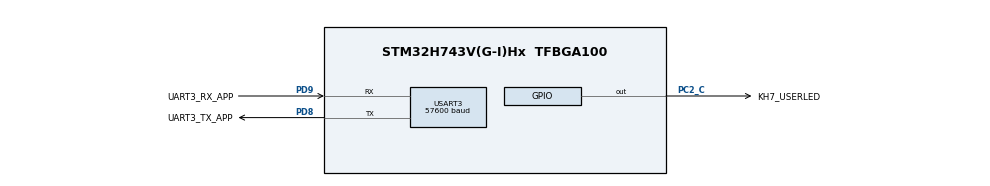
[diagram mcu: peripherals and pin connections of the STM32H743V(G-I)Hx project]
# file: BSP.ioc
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CORTEX_M7.default_mode_Activation=0
Mcu.Family=STM32H7
Mcu.Name=STM32H743V(G-I)Hx
Mcu.Package=TFBGA100
NVIC.PriorityGroup=NVIC_PRIORITYGROUP_4
PA13\ (JTMS/SWDIO).Mode=Serial_Wire
PA13\ (JTMS/SWDIO).Signal=DEBUG_JTMS-SWDIO
PA14\ (JTCK/SWCLK).Mode=Serial_Wire
PA14\ (JTCK/SWCLK).Signal=DEBUG_JTCK-SWCLK
PC2_C.GPIO_Label=KH7_USERLED
PC2_C.GPIO_ModeDefaultOutputPP=GPIO_MODE_OUTPUT_OD
PC2_C.GPIO_PuPd=GPIO_NOPULL
PC2_C.GPIO_Speed=GPIO_SPEED_FREQ_MEDIUM
PC2_C.PinState=GPIO_PIN_RESET
PC2_C.Signal=GPIO_Output
PD8.GPIO_Label=UART3_TX_APP
PD8.GPIO_Speed=GPIO_SPEED_FREQ_HIGH
PD8.Mode=Asynchronous
PD8.Signal=USART3_TX
PD9.GPIO_Label=UART3_RX_APP
PD9.GPIO_Speed=GPIO_SPEED_FREQ_HIGH
PD9.Mode=Asynchronous
PD9.Signal=USART3_RX
ProjectManager.HeapSize=0x200
ProjectManager.StackSize=0x400
ProjectManager.TargetToolchain=STM32CubeIDE
RCC.ADCFreq_Value=129000000
RCC.APB1Freq_Value=32000000
RCC.APB2Freq_Value=64000000
RCC.APB3Freq_Value=64000000
RCC.APB4Freq_Value=64000000
RCC.CortexFreq_Value=64000000
RCC.D2PPRE1=RCC_APB1_DIV2
RCC.HCLKFreq_Value=64000000
RCC.SYSCLKFreq_VALUE=64000000
RCC.USBFreq_Value=129000000
USART3.BaudRate=57600
USART3.VirtualMode-Asynchronous=VM_ASYNC
board=custom

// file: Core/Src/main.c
/* USER CODE BEGIN Header */
/**
  ******************************************************************************
  * @file           : main.c
  * @brief          : Main program body
  ******************************************************************************
  * @attention
  *
  * Copyright (c) 2023 STMicroelectronics.
  * All rights reserved.
  *
  * This software is licensed under terms that can be found in the LICENSE file
  * in the root directory of this software component.
  * If no LICENSE file comes with this software, it is provided AS-IS.
  *
  ******************************************************************************
  */
/* USER CODE END Header */
#include "main.h"

/* USER CODE BEGIN Includes */
#include <stdio.h>
#include "app.h"

/* USER CODE END Includes */

UART_HandleTypeDef huart3;

/* USER CODE BEGIN PV */
uint8_t tx_buff[]="\r\n #================ ST Autopilot Test Platform ================# \r\n";
/* USER CODE END PV */

void SystemClock_Config(void);
static void MX_GPIO_Init(void);
static void MX_USART3_UART_Init(void);

/* USER CODE BEGIN 0 */

#if defined(__GNUC__)
int _write(int fd, char * ptr, int len)
{
  uint8_t c_ret[1]="\r";
  UNUSED(fd);
  HAL_UART_Transmit(&huart3, (uint8_t *) ptr, len, HAL_MAX_DELAY);
  HAL_UART_Transmit(&huart3, (uint8_t *)c_ret,1, HAL_MAX_DELAY);
  return len;
}
#elif defined (__ICCARM__)
#include "LowLevelIOInterface.h"
size_t __write(int handle, const unsigned char * buffer, size_t size)
{
  HAL_UART_Transmit(&huart3, (uint8_t *) buffer, size, HAL_MAX_DELAY);
  return size;
}
#elif defined (__CC_ARM)
int fputc(int ch, FILE *f)
{
    HAL_UART_Transmit(&huart3, (uint8_t *)&ch, 1, HAL_MAX_DELAY);
    return ch;
}
#endif

// OR:

// Add syscalls.c with GCC

#ifdef __GNUC__
#define PUTCHAR_PROTOTYPE int __io_putchar(int ch)
#else
#define PUTCHAR_PROTOTYPE int fputc(int ch, FILE *f)
#endif /* __GNUC__ */

/**
  * @brief  Retargets the C library printf function to the USART.
  * @param  None
  * @retval None
  */
PUTCHAR_PROTOTYPE
{
  uint8_t c_ret[1]="\r";
  HAL_UART_Transmit(&huart3, (uint8_t *)&ch, 1, HAL_MAX_DELAY);
  HAL_UART_Transmit(&huart3, (uint8_t *)&c_ret,1, HAL_MAX_DELAY);
  return ch;
}
/* USER CODE END 0 */

int main(void)
{

  /* MCU Configuration--------------------------------------------------------*/

  /* Reset of all peripherals, Initializes the Flash interface and the Systick. */
  HAL_Init();

  /* Configure the system clock */
  SystemClock_Config();

  /* Initialize all configured peripherals */
  MX_GPIO_Init();
  MX_USART3_UART_Init();
  /* USER CODE BEGIN 2 */

  printf("\r\n #================ ST Autopilot Test Platform ================# \r\n");
  //HAL_UART_Transmit(&huart3, tx_buff, sizeof(tx_buff), HAL_MAX_DELAY);
  loop();
  /* USER CODE END 2 */

  /* Infinite loop */
  /* USER CODE BEGIN WHILE */
  while (1)
  {
#if 0
	  for(int i=0;i<100;i++)
	  {
		  HAL_GPIO_TogglePin(KH7_USERLED_GPIO_Port,KH7_USERLED_Pin);
		  HAL_Delay(100);
	  }
	  for(int i=0;i<50;i++)
	  {
		  HAL_GPIO_TogglePin(KH7_USERLED_GPIO_Port,KH7_USERLED_Pin);
		  HAL_Delay(200);
	  }
	  for(int i=0;i<20;i++)
	  {
		  HAL_GPIO_TogglePin(KH7_USERLED_GPIO_Port,KH7_USERLED_Pin);
		  HAL_Delay(300);
	  }
	  for(int i=0;i<10;i++)
	  {
		  HAL_GPIO_TogglePin(KH7_USERLED_GPIO_Port,KH7_USERLED_Pin);
		  HAL_Delay(500);
	  }
#endif
    /* USER CODE END WHILE */

  }
}

void SystemClock_Config(void)
{
  RCC_OscInitTypeDef RCC_OscInitStruct = {0};
  RCC_ClkInitTypeDef RCC_ClkInitStruct = {0};

  /** Supply configuration update enable
  */
  HAL_PWREx_ConfigSupply(PWR_LDO_SUPPLY);

  /** Configure the main internal regulator output voltage
  */
  __HAL_PWR_VOLTAGESCALING_CONFIG(PWR_REGULATOR_VOLTAGE_SCALE3);

  while(!__HAL_PWR_GET_FLAG(PWR_FLAG_VOSRDY)) {}

  /** Initializes the RCC Oscillators according to the specified parameters
  * in the RCC_OscInitTypeDef structure.
  */
  RCC_OscInitStruct.OscillatorType = RCC_OSCILLATORTYPE_HSI;
  RCC_OscInitStruct.HSIState = RCC_HSI_DIV1;
  RCC_OscInitStruct.HSICalibrationValue = RCC_HSICALIBRATION_DEFAULT;
  RCC_OscInitStruct.PLL.PLLState = RCC_PLL_NONE;
  if (HAL_RCC_OscConfig(&RCC_OscInitStruct) != HAL_OK)
  {
    Error_Handler();
  }

  /** Initializes the CPU, AHB and APB buses clocks
  */
  RCC_ClkInitStruct.ClockType = RCC_CLOCKTYPE_HCLK|RCC_CLOCKTYPE_SYSCLK
                              |RCC_CLOCKTYPE_PCLK1|RCC_CLOCKTYPE_PCLK2
                              |RCC_CLOCKTYPE_D3PCLK1|RCC_CLOCKTYPE_D1PCLK1;
  RCC_ClkInitStruct.SYSCLKSource = RCC_SYSCLKSOURCE_HSI;
  RCC_ClkInitStruct.SYSCLKDivider = RCC_SYSCLK_DIV1;
  RCC_ClkInitStruct.AHBCLKDivider = RCC_HCLK_DIV1;
  RCC_ClkInitStruct.APB3CLKDivider = RCC_APB3_DIV1;
  RCC_ClkInitStruct.APB1CLKDivider = RCC_APB1_DIV2;
  RCC_ClkInitStruct.APB2CLKDivider = RCC_APB2_DIV1;
  RCC_ClkInitStruct.APB4CLKDivider = RCC_APB4_DIV1;

  if (HAL_RCC_ClockConfig(&RCC_ClkInitStruct, FLASH_LATENCY_1) != HAL_OK)
  {
    Error_Handler();
  }
}

static void MX_USART3_UART_Init(void)
{

  huart3.Instance = USART3;
  huart3.Init.BaudRate = 57600;
  huart3.Init.WordLength = UART_WORDLENGTH_8B;
  huart3.Init.StopBits = UART_STOPBITS_1;
  huart3.Init.Parity = UART_PARITY_NONE;
  huart3.Init.Mode = UART_MODE_TX_RX;
  huart3.Init.HwFlowCtl = UART_HWCONTROL_NONE;
  huart3.Init.OverSampling = UART_OVERSAMPLING_16;
  huart3.Init.OneBitSampling = UART_ONE_BIT_SAMPLE_DISABLE;
  huart3.Init.ClockPrescaler = UART_PRESCALER_DIV1;
  huart3.AdvancedInit.AdvFeatureInit = UART_ADVFEATURE_NO_INIT;
  if (HAL_UART_Init(&huart3) != HAL_OK)
  {
    Error_Handler();
  }
  if (HAL_UARTEx_SetTxFifoThreshold(&huart3, UART_TXFIFO_THRESHOLD_1_8) != HAL_OK)
  {
    Error_Handler();
  }
  if (HAL_UARTEx_SetRxFifoThreshold(&huart3, UART_RXFIFO_THRESHOLD_1_8) != HAL_OK)
  {
    Error_Handler();
  }
  if (HAL_UARTEx_DisableFifoMode(&huart3) != HAL_OK)
  {
    Error_Handler();
  }

}

static void MX_GPIO_Init(void)
{
  GPIO_InitTypeDef GPIO_InitStruct = {0};

  /* GPIO Ports Clock Enable */
  __HAL_RCC_GPIOA_CLK_ENABLE();
  __HAL_RCC_GPIOC_CLK_ENABLE();
  __HAL_RCC_GPIOD_CLK_ENABLE();

  /*Configure GPIO pin Output Level */
  HAL_GPIO_WritePin(KH7_USERLED_GPIO_Port, KH7_USERLED_Pin, GPIO_PIN_RESET);

  /*Configure GPIO pin : KH7_USERLED_Pin */
  GPIO_InitStruct.Pin = KH7_USERLED_Pin;
  GPIO_InitStruct.Mode = GPIO_MODE_OUTPUT_OD;
  GPIO_InitStruct.Pull = GPIO_NOPULL;
  GPIO_InitStruct.Speed = GPIO_SPEED_FREQ_MEDIUM;
  HAL_GPIO_Init(KH7_USERLED_GPIO_Port, &GPIO_InitStruct);

}

void Error_Handler(void)
{
  __disable_irq();
  while (1)
  {
  }
}
